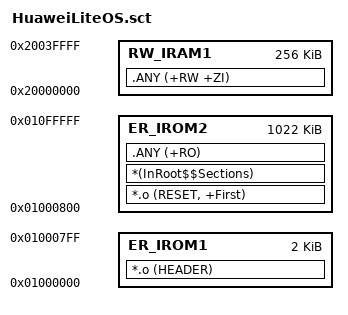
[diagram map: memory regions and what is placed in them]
; *************************************************************
; *** Scatter-Loading Description File generated by uVision ***
; *************************************************************

LR_IROM1 0x01000000 0x00000800  {    ; load region size_region
  ER_IROM1 0x01000000 0x00000800  {  ; load address = execution address
   *.o (HEADER)
  }

}

LR_IROM2 0x01000800 0x000FF800  {    ; load region size_region
  ER_IROM2 0x01000800 0x000FF800  {  ; load address = execution address
   *.o (RESET, +First)
   *(InRoot$$Sections)
   .ANY (+RO)
  }
  RW_IRAM1 0x20000000 0x00040000  {  ; RW data
   .ANY (+RW +ZI)
  }
}

